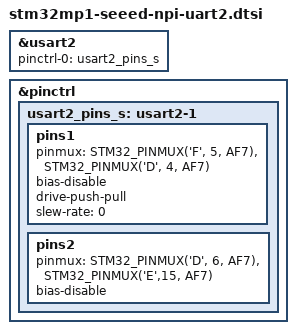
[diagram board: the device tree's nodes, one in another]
// Peter Yang, 20191108
// NPi Expansion (UART)

&usart2 {
	pinctrl-names = "default";
	pinctrl-0 = <&usart2_pins_s>;
	status = "okay";
};

		&pinctrl {
			usart2_pins_s: usart2-1 {
				pins1 {
					pinmux = <STM32_PINMUX('F', 5, AF7)>, /* USART2_TX */
						 <STM32_PINMUX('D', 4, AF7)>; /* USART2_RTS */
					bias-disable;
					drive-push-pull;
					slew-rate = <0>;
				};
				pins2 {
					pinmux = <STM32_PINMUX('D', 6, AF7)>, /* USART2_RX */
						 <STM32_PINMUX('E',15, AF7)>; /* USART2_CTS_NSS */
					bias-disable;
				};
			};
		};

